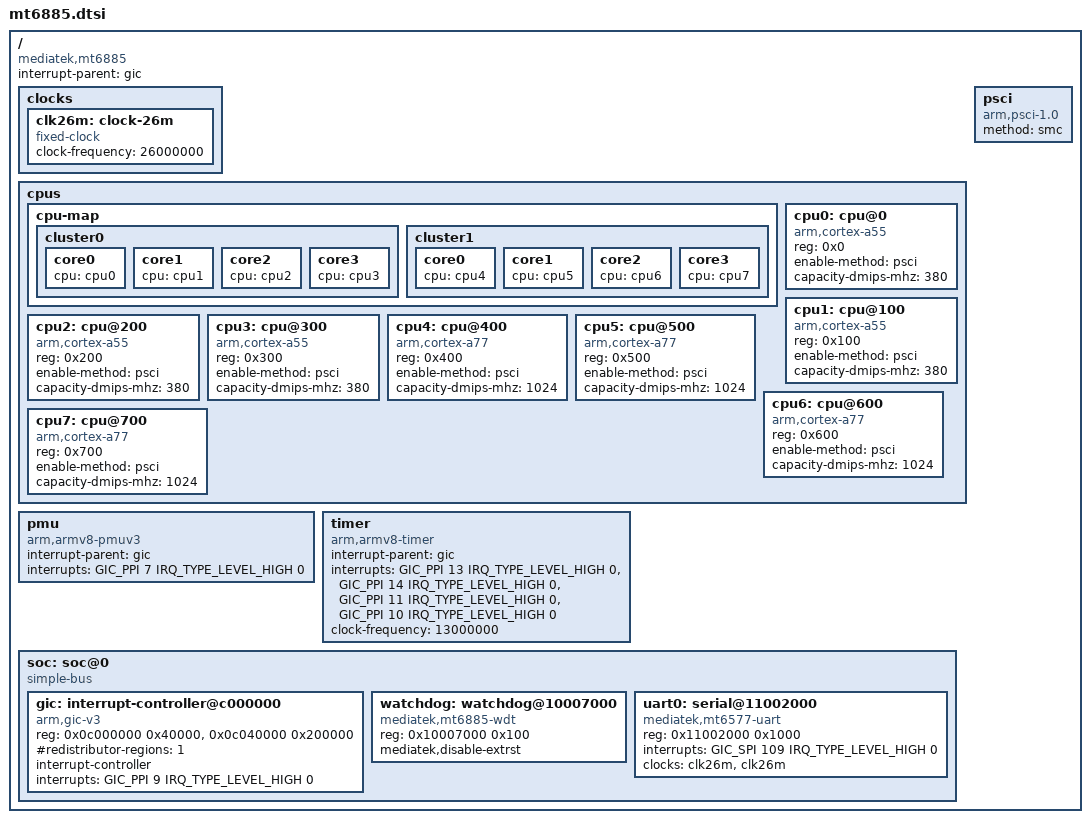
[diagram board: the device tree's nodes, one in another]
// SPDX-License-Identifier: (GPL-2.0-only OR BSD-2-Clause)
/*
 * MediaTek MT6885 (Dimensity 1000 series) SoC
 *
 * Minimal SoC description for the Xiaomi Redmi K30 Ultra (cezanne,
 * MT6889Z) mainline bring-up.  Register addresses, interrupt numbers and
 * the timer frequency come from the stock Android device tree shipped in
 * the device's boot image.
 *
 * Only the blocks needed before the first userspace milestone are
 * described here.  Peripheral nodes are added together with the matching
 * mainline drivers, never as stubs that could bind a driver at a wrong
 * address.
 */

#include <dt-bindings/interrupt-controller/arm-gic.h>
#include <dt-bindings/interrupt-controller/irq.h>

/ {
	compatible = "mediatek,mt6885";
	#address-cells = <2>;
	#size-cells = <2>;

	interrupt-parent = <&gic>;

	clocks {
		clk26m: clock-26m {
			compatible = "fixed-clock";
			#clock-cells = <0>;
			clock-frequency = <26000000>;
		};
	};

	cpus {
		#address-cells = <1>;
		#size-cells = <0>;

		cpu-map {
			cluster0 {
				core0 {
					cpu = <&cpu0>;
				};
				core1 {
					cpu = <&cpu1>;
				};
				core2 {
					cpu = <&cpu2>;
				};
				core3 {
					cpu = <&cpu3>;
				};
			};

			cluster1 {
				core0 {
					cpu = <&cpu4>;
				};
				core1 {
					cpu = <&cpu5>;
				};
				core2 {
					cpu = <&cpu6>;
				};
				core3 {
					cpu = <&cpu7>;
				};
			};
		};

		cpu0: cpu@0 {
			device_type = "cpu";
			compatible = "arm,cortex-a55";
			reg = <0x0>;
			enable-method = "psci";
			capacity-dmips-mhz = <380>;
		};

		cpu1: cpu@100 {
			device_type = "cpu";
			compatible = "arm,cortex-a55";
			reg = <0x100>;
			enable-method = "psci";
			capacity-dmips-mhz = <380>;
		};

		cpu2: cpu@200 {
			device_type = "cpu";
			compatible = "arm,cortex-a55";
			reg = <0x200>;
			enable-method = "psci";
			capacity-dmips-mhz = <380>;
		};

		cpu3: cpu@300 {
			device_type = "cpu";
			compatible = "arm,cortex-a55";
			reg = <0x300>;
			enable-method = "psci";
			capacity-dmips-mhz = <380>;
		};

		cpu4: cpu@400 {
			device_type = "cpu";
			compatible = "arm,cortex-a77";
			reg = <0x400>;
			enable-method = "psci";
			capacity-dmips-mhz = <1024>;
		};

		cpu5: cpu@500 {
			device_type = "cpu";
			compatible = "arm,cortex-a77";
			reg = <0x500>;
			enable-method = "psci";
			capacity-dmips-mhz = <1024>;
		};

		cpu6: cpu@600 {
			device_type = "cpu";
			compatible = "arm,cortex-a77";
			reg = <0x600>;
			enable-method = "psci";
			capacity-dmips-mhz = <1024>;
		};

		cpu7: cpu@700 {
			device_type = "cpu";
			compatible = "arm,cortex-a77";
			reg = <0x700>;
			enable-method = "psci";
			capacity-dmips-mhz = <1024>;
		};
	};

	pmu {
		compatible = "arm,armv8-pmuv3";
		interrupt-parent = <&gic>;
		interrupts = <GIC_PPI 7 IRQ_TYPE_LEVEL_HIGH 0>;
	};

	psci {
		compatible = "arm,psci-1.0";
		method = "smc";
	};

	timer {
		compatible = "arm,armv8-timer";
		interrupt-parent = <&gic>;
		interrupts = <GIC_PPI 13 IRQ_TYPE_LEVEL_HIGH 0>,
			     <GIC_PPI 14 IRQ_TYPE_LEVEL_HIGH 0>,
			     <GIC_PPI 11 IRQ_TYPE_LEVEL_HIGH 0>,
			     <GIC_PPI 10 IRQ_TYPE_LEVEL_HIGH 0>;
		clock-frequency = <13000000>;
	};

	soc: soc@0 {
		compatible = "simple-bus";
		#address-cells = <1>;
		#size-cells = <1>;
		ranges = <0x0 0x0 0x0 0x20000000>;

		gic: interrupt-controller@c000000 {
			compatible = "arm,gic-v3";
			reg = <0x0c000000 0x40000>,
			      <0x0c040000 0x200000>;
			#interrupt-cells = <4>;
			#redistributor-regions = <1>;
			interrupt-controller;
			interrupts = <GIC_PPI 9 IRQ_TYPE_LEVEL_HIGH 0>;
		};

		/*
		 * AP watchdog.  LK leaves it running, so the mainline driver
		 * must take it over (or the board reboots while booting).
		 * Keep the reset internal to the AP: the external reset line
		 * is not wired the way the generic driver expects.
		 */
		watchdog: watchdog@10007000 {
			compatible = "mediatek,mt6885-wdt",
				     "mediatek,mt6589-wdt";
			reg = <0x10007000 0x100>;
			mediatek,disable-extrst;
		};

		/*
		 * The console UART is the second controller instance on this
		 * SoC (the stock tree calls it apuart0 at 0x11002000).
		 * LK already programmed the pins and the divisor; the fixed
		 * 26 MHz reference keeps the mainline driver usable without
		 * the (not yet ported) MT6885 clock controller.
		 */
		uart0: serial@11002000 {
			compatible = "mediatek,mt6577-uart";
			reg = <0x11002000 0x1000>;
			interrupts = <GIC_SPI 109 IRQ_TYPE_LEVEL_HIGH 0>;
			clocks = <&clk26m>, <&clk26m>;
			clock-names = "baud", "bus";
			status = "okay";
		};
	};
};
